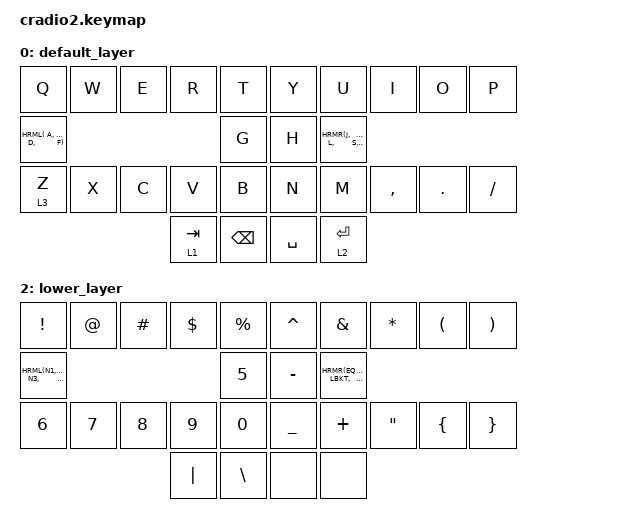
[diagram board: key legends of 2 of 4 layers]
#define ZMK_POINTING_DEFAULT_MOVE_VAL 800
#define ZMK_POINTING_DEFAULT_SCRL_VAL 10

#include <behaviors.dtsi>
#include <dt-bindings/zmk/keys.h>
#include <dt-bindings/zmk/bt.h>
#include <dt-bindings/zmk/outputs.h>
#include <dt-bindings/zmk/pointing.h>

// Home row mods macro
#define HRML(k1,k2,k3,k4) &hml LGUI k1  &hml LALT k2  &hml LCTRL k3  &hml LSHFT k4
#define HRMR(k1,k2,k3,k4) &hmr RSHFT k1  &hmr RCTRL k2  &hmr RALT k3  &hmr RGUI k4
#define HRMLS(k1,k2,k3,k4) &hmls LGUI k1  &hmls LALT k2  &hmls LCTRL k3 &hmls LSHIFT k4

#define ht_tt 200
#define ht_qt 125
#define ht_rpi 100
#define combo_time 30
/ {
    behaviors {
        lt: layer_tap {
            compatible = "zmk,behavior-hold-tap";
            #binding-cells = <2>;
            flavor = "tap-preferred";
            tapping-term-ms = <180>;
            bindings = <&mo>, <&kp>;
            quick-tap-ms = <150>;
        };

        hml: home_row_mod_left {
            compatible = "zmk,behavior-hold-tap";
            #binding-cells = <2>;
            flavor = "tap-preferred";
            require-prior-idle-ms = <ht_rpi>;
            tapping-term-ms = <ht_tt>;
            quick-tap-ms = <ht_qt>;
            bindings = <&kp>, <&kp>;
            hold-trigger-on-release;
        };
        hmr: home_row_mod_right {
            compatible = "zmk,behavior-hold-tap";
            #binding-cells = <2>;
            flavor = "balanced";
            require-prior-idle-ms = <ht_rpi>;
            tapping-term-ms = <ht_tt>;
            quick-tap-ms = <ht_qt>;
            bindings = <&kp>, <&kp>;
            hold-trigger-on-release;
        };
        sk: sticky_key {
            release-after-ms = <2000>;
            quick-release;
            ignore-modifiers;
        };

        hmls: home_row_mod_left_sticky {
            compatible = "zmk,behavior-hold-tap";
            #binding-cells = <2>;
            flavor = "hold-preferred";
            require-prior-idle-ms = <ht_rpi>;
            tapping-term-ms = <ht_tt>;
            quick-tap-ms = <ht_qt>;
            bindings = <&kp>, <&sk>;
            hold-trigger-on-release;
        };
    };
    combos {
        compatible = "zmk,combos";
        combo_esc {
            timeout-ms = <combo_time>;
            key-positions = <2 7>;
            bindings = <&kp ESC>;
            layers = <0>;
            require-prior-idle-ms = <100>;
        };
        combo_capword{
            timeout-ms = <combo_time>;
            key-positions = <3 6>;
            bindings = <&caps_word>;
            layers = <0>;
            require-prior-idle-ms = <100>;
        };
        combo_caplock {
            timeout-ms = <combo_time>;
            key-positions = <0 9>;
            bindings = <&kp CAPS>;
            layers = <0>;
            require-prior-idle-ms = <100>;
        };
        combo_delete{
            timeout-ms = <combo_time>;
            key-positions = <7 8>;
            bindings = <&kp DEL>;
            layers = <0>;
            require-prior-idle-ms = <100>;
        };
        combo_printscreen{
            timeout-ms = <combo_time>;
            key-positions = <5 6>;
            bindings = <&kp PSCRN>;
            layers = <0>;
            require-prior-idle-ms = <100>;
        };
    };

    keymap {
        compatible = "zmk,keymap";
        default_layer {
            bindings = <
                //╭──────────┬──────────┬──────────┬──────────┬──────────╮   ╭──────────┬──────────┬──────────┬──────────┬──────────╮
                //│  Q       │  W       │  E       │  R       │  T       │   │  Y       │  U       │  I       │  O       │   P      │
                    &kp Q      &kp W      &kp E      &kp R      &kp T          &kp Y      &kp U     &kp I        &kp O      &kp P 
                //├──────────┼──────────┼──────────┼──────────┼──────────┤   ├──────────┼──────────┼──────────┼──────────┼──────────┤
                //│  A       │  S       │  D       │  F       │  G       │   │  H       │  J       │  K       │  L       │  ; :     │
                    HRML( A,     S,        D,           F)      &kp G          &kp H      HRMR(J,      K,        L,         SEMI)
                //├──────────┼──────────┼──────────┼──────────┼──────────┤   ├──────────┼──────────┼──────────┼──────────┼──────────┤
                //│  Z       │  X       │  C       │  V       │  B       │   │  N       │  M       │ , <      │ . >      │ / ?      │
                    &lt 3 Z   &kp X      &kp C      &kp V      &kp B          &kp N      &kp M      &kp COMMA  &kp DOT    &kp FSLH
                //╰──────────┴──────────┴──────────┼──────────┼──────────┤   ├──────────┼──────────┼──────────┴──────────┴──────────╯
                                                    &lt 1 TAB   &kp BSPC       &kp SPACE &lt 2 ENTER
                //                                 ╰──────────┴──────────╯   ╰──────────┴──────────╯
            >;
        };

        raise_layer {
            bindings = <
                //╭──────────┬──────────┬──────────┬──────────┬──────────╮   ╭──────────┬──────────┬──────────┬──────────┬──────────╮
                //│    F1    │    F2    │    F3    │    F4    │    F5    │   │    F6    │   F7     │    F8    │   F9     │   F10    │
                     &kp F1    &kp F2     &kp F3     &kp F4     &kp F5         &kp F6      &kp F7     &kp F8     &kp F9     &kp F10
                //├──────────┼──────────┼──────────┼──────────┼──────────┤   ├──────────┼──────────┼──────────┼──────────┼──────────┤
                //│          │          │          │          │          │   │   left   │  down    │   up     │  right   │          │
                   HRMLS(LGUI,  LALT,      LCTRL,     LSHFT)     &none          &kp LEFT   &kp DOWN   &kp UP     &kp RIGHT   &kp F11
                //├──────────┼──────────┼──────────┼──────────┼──────────┤   ├──────────┼──────────┼──────────┼──────────┼──────────┤
                //│    `     │    ~     │          │          │          │   │ m left   │ m down   │  m up    │ m  right │  ENTER   │
                   &kp GRAVE   &kp TILDE  &none      &none       &none  &mmv MOVE_LEFT &mmv MOVE_DOWN &mmv MOVE_UP &mmv MOVE_RIGHT  &kp F12
                //╰──────────┴──────────┴──────────┼──────────┼──────────┤   ├──────────┼──────────┼──────────┴──────────┴──────────╯
                                                     &none       &none          &mkp LCLK  &mkp RCLK
                //                                 ╰──────────┴──────────╯   ╰──────────┴──────────╯
            >;
        };

        lower_layer {
            bindings = <
                //╭──────────┬──────────┬──────────┬──────────┬──────────╮   ╭──────────┬──────────┬──────────┬──────────┬──────────╮
                //│     !    │    @     │    #     │    $     │    %     │   │    ^     │    &     │     *    │    (     │    )     │
                    &kp EXCL   &kp AT     &kp HASH   &kp DLLR   &kp PRCNT      &kp CARET  &kp AMPS   &kp ASTRK  &kp LPAR   &kp RPAR
                //├──────────┼──────────┼──────────┼──────────┼──────────┤   ├──────────┼──────────┼──────────┼──────────┼──────────┤
                //│    1     │    2     │    3     │    4     │    5     │   │    -     │    =     │    '     │    [     │    ]     │
                    HRML(N1,     N2,        N3,         N4 )      &kp N5       &kp MINUS HRMR(EQUAL,   SQT,      LBKT,     RBKT)
                //├──────────┼──────────┼──────────┼──────────┼──────────┤   ├──────────┼──────────┼──────────┼──────────┼──────────┤
                //│    6     │    7     │    8     │    9     │    0     │   │    _     │    +     │    "     │    {     │    }     │
                    &kp N6     &kp N7     &kp N8     &kp N9      &kp N0        &kp UNDER  &kp PLUS   &kp DQT    &kp LBRC   &kp RBRC
                //╰──────────┴──────────┴──────────┼──────────┼──────────┤   ├──────────┼──────────┼──────────┴──────────┴──────────╯
                                                      &kp PIPE    &kp BSLH    &none        &none
                //                                 ╰──────────┴──────────╯   ╰──────────┴──────────╯
            >;
        };
        setting_layer{
            bindings = <
                //╭──────────┬──────────┬──────────┬──────────┬──────────╮   ╭──────────┬──────────┬──────────┬──────────┬──────────╮
                //│          │          │          │          │          │   │          │          │          │          │          │
                    &none       &none      &none      &none    &bt BT_CLR  &bt BT_SEL 0 &bt BT_SEL 1 &bt BT_SEL 2 &bt BT_SEL 3 &bt BT_SEL 4
                //├──────────┼──────────┼──────────┼──────────┼──────────┤   ├──────────┼──────────┼──────────┼──────────┼──────────┤
                //│          │          │          │          │          │   │          │          │          │          │          │
                     &none      &none     &none       &none      &none       &kp C_MUTE &kp C_VOL_UP &kp C_VOL_DN &kp C_BRI_UP &kp C_BRI_DN
                //├──────────┼──────────┼──────────┼──────────┼──────────┤   ├──────────┼──────────┼──────────┼──────────┼──────────┤
                //│          │          │          │          │          │   │          │          │          │          │          │
                    &none       &none      &none      &none      &none         &none    &kp C_NEXT  &kp C_PREV   &none     &out OUT_TOG
                //╰──────────┴──────────┴──────────┼──────────┼──────────┤   ├──────────┼──────────┼──────────┴──────────┴──────────╯
                                                     &none      &none          &kp C_PP    &none 
                //                                 ╰──────────┴──────────╯   ╰──────────┴──────────╯
            >;
        };
    };
};
